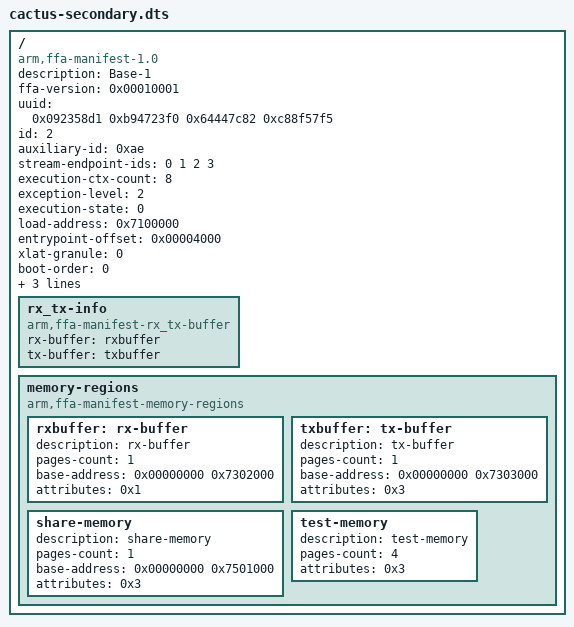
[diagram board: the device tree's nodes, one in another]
/*
 * Copyright (c) 2019-2021, Arm Limited. All rights reserved.
 *
 * SPDX-License-Identifier: BSD-3-Clause
 *
 * This file is a Partition Manifest (PM) for a minimal Secure Partition (SP)
 * that has additional optional properties defined.
 *
 */

/dts-v1/;

/ {
	compatible = "arm,ffa-manifest-1.0";

	/* Properties */
	description = "Base-1";
	ffa-version = <0x00010001>; /* 31:16 - Major, 15:0 - Minor */
	uuid = <0x092358d1 0xb94723f0 0x64447c82 0xc88f57f5>;
	id = <2>;
	auxiliary-id = <0xae>;
	stream-endpoint-ids = <0 1 2 3>;
	execution-ctx-count = <8>;
	exception-level = <2>; /* S-EL1 */
	execution-state = <0>; /* AARCH64 */
	load-address = <0x7100000>;
	entrypoint-offset = <0x00004000>;
	xlat-granule = <0>; /* 4KiB */
	boot-order = <0>;
	messaging-method = <3>; /* Direct messaging only */
	notification-support; /* Support receipt of notifications. */
	run-time-model = <0>; /* Run to completion */

	rx_tx-info {
		compatible = "arm,ffa-manifest-rx_tx-buffer";
		rx-buffer = <&rxbuffer>;
		tx-buffer = <&txbuffer>;
	};

	memory-regions {
		compatible = "arm,ffa-manifest-memory-regions";

		rxbuffer: rx-buffer {
			description = "rx-buffer";
			pages-count = <1>;
			base-address = <0x00000000 0x7302000>;
			attributes = <0x1>; /* read-only */
		};

		txbuffer: tx-buffer {
			description = "tx-buffer";
			pages-count = <1>;
			base-address = <0x00000000 0x7303000>;
			attributes = <0x3>; /* read-write */
		};

		/* Memory to be shared in memory sharing tests. */
		share-memory {
			description = "share-memory";
			pages-count = <1>;
			base-address = <0x00000000 0x7501000>;
			attributes = <0x3>; /* read-write */
		};

		/* Without optional base-address */
		test-memory {
			description = "test-memory";
			pages-count = <4>;
			attributes = <0x3>; /* read-write */
		};
	};
};
